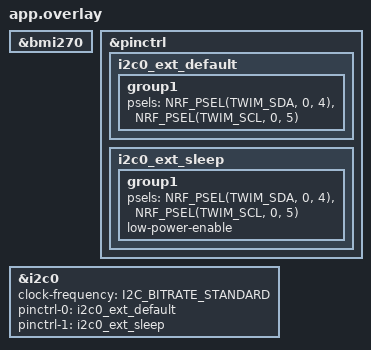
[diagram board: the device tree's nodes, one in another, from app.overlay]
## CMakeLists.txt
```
# Thingy:53 gait sensor node — integration firmware.
# Each sensor/radio module is compiled only when its Kconfig switch is on (see Kconfig).
# Every .c file is listed explicitly: a missing one gives "undefined reference".

cmake_minimum_required(VERSION 3.20.0)
find_package(Zephyr REQUIRED HINTS $ENV{ZEPHYR_BASE})
project(gait_node)

# Lets sources include "system/system_config.h", "imu/imu.h", ... from any subfolder
target_include_directories(app PRIVATE src src/plantar)

target_sources(app PRIVATE
    src/main.c
    src/data/data_queue.c
)

target_sources_ifdef(CONFIG_GAIT_IMU app PRIVATE
    src/imu/imu.c
    src/imu/imu_thread.c
)

target_sources_ifdef(CONFIG_GAIT_PLANTAR app PRIVATE
    src/plantar/fsr402.c
    src/plantar/plantar_thread.c
)

target_sources_ifdef(CONFIG_GAIT_BLE app PRIVATE
    src/ble/gait_ble.c
)

# BLE consumer requires both BLE and Plantar modules
if(CONFIG_GAIT_BLE AND CONFIG_GAIT_PLANTAR)
    target_sources(app PRIVATE src/ble/ble_thread.c)
endif()

# Fake data source for BLE testing without sensors (see Kconfig GAIT_MOCK_DATA)
target_sources_ifdef(CONFIG_GAIT_MOCK_DATA app PRIVATE
    src/mock/mock_signal.c
    src/mock/mock_thread.c
)
```

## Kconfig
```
# Module switches for the gait node. Turn a module off in prj.conf if it is not ready;
# the rest of the firmware still builds and runs.

menu "Gait node modules"

config GAIT_IMU
	bool "BMI270 IMU module (src/imu)"
	default y
	select SENSOR

config GAIT_PLANTAR
	bool "FSR 402 plantar pressure module via Adafruit ADS7128 (I2C)"
	default n
	depends on I2C
	help
	  Enable the six-channel FSR402 interface using the Adafruit ADS7128
	  8-channel, 12-bit ADC over the dedicated external I2C bus.

config GAIT_BLE
	bool "BLE streaming to the i.MX95 (src/ble)"
	default n
	help
	  Off until protocol/BLE_GAIT_PROTOCOL.md is agreed. When off, samples
	  are printed to the USB serial console instead.

config GAIT_MOCK_DATA
	bool "Send fake IMU/FSR data over BLE (no sensors needed)"
	default n
	depends on GAIT_BLE && GAIT_PLANTAR
	help
	  Skips imu_init()/fsr402_init() and the real sensor threads. A mock thread
	  generates a walking-like signal (stride 1.1 s) at 100 Hz instead. Use it to
	  test BLE and the receiver. Turn it off for real measurements.

endmenu

source "Kconfig.zephyr"
```

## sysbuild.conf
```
# The nRF5340 has two cores: this app runs on the
# application core, the BLE radio lives on the network core and needs its own image.

# Thingy:53 still relies on the Partition Manager; without it the network-core
# build fails with "undefined node label 's0_partition'".
SB_CONFIG_PARTITION_MANAGER=y

# Network core image: BLE controller (ipc_radio, HCI over IPC) instead of an empty image
SB_CONFIG_NETCORE_IPC_RADIO=y
SB_CONFIG_NETCORE_IPC_RADIO_BT_HCI_IPC=y

# One merged hex for app + network core
SB_CONFIG_MERGED_HEX_FILES=y

SB_CONFIG_BOOTLOADER_MCUBOOT=y
```

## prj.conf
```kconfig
# Console over USB (the board default USB stack provides the CDC ACM console)
CONFIG_STDOUT_CONSOLE=y
CONFIG_CBPRINTF_FP_SUPPORT=y
CONFIG_UART_LINE_CTRL=y

# MCUboot: app-side image manager, lets the app confirm a new image after boot.
# Optional, but needed if the app calls boot_write_img_confirmed().
CONFIG_MCUBOOT_IMG_MANAGER=y

# Modules
CONFIG_GAIT_IMU=y
CONFIG_GAIT_PLANTAR=y
CONFIG_GAIT_BLE=y

# ADS7128 communicates over I2C (not the nRF5340 internal SAADC).
CONFIG_I2C=y

# Needed by the BMI270 sensor driver
CONFIG_SENSOR=y

# Needed by the BLE module. Comment out together with CONFIG_GAIT_BLE=n.
CONFIG_BT=y
CONFIG_BT_PERIPHERAL=y
CONFIG_BT_DEVICE_NAME="GaitNode"
# Ask the central for a 7.5-15 ms connection interval (units of 1.25 ms)
CONFIG_BT_PERIPHERAL_PREF_MIN_INT=6
CONFIG_BT_PERIPHERAL_PREF_MAX_INT=12
CONFIG_BT_PERIPHERAL_PREF_LATENCY=0
CONFIG_BT_PERIPHERAL_PREF_TIMEOUT=400
# main() now runs printf with floats plus the BLE calls
CONFIG_MAIN_STACK_SIZE=4096
# More TX buffers so ~200 notifications/s (IMU + FSR at 100 Hz) are not dropped
CONFIG_BT_L2CAP_TX_MTU=247
CONFIG_BT_BUF_ACL_RX_SIZE=251
CONFIG_BT_BUF_ACL_TX_SIZE=251
CONFIG_BT_BUF_ACL_TX_COUNT=7
CONFIG_BT_L2CAP_TX_BUF_COUNT=7
CONFIG_BT_BUF_EVT_RX_COUNT=10

# Test BLE without sensors (fake walking data). Set to n for real measurements.
CONFIG_GAIT_MOCK_DATA=y
```

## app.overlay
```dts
/*
 * Thingy:53 gait_node overlay
 *
 * BMI270 remains enabled on the board's existing SPI bus.
 *
 * ADS7128 uses a dedicated external I2C bus
 * on the Thingy:53 expansion pins:
 *   P0.04 = EXP_BOARD_PIN1 = SDA
 *   P0.05 = EXP_BOARD_PIN2 = SCL
 *
 * ADS7128 factory I2C address: 0x10
 *
 * This overlay uses i2c0 on P0.04/P0.05,
 * not the Thingy:53 onboard-sensor i2c1 bus.
 */

#include <zephyr/dt-bindings/pinctrl/nrf-pinctrl.h>


/* IMU owner: BMI270 on SPI, unchanged. */
&bmi270 {
    status = "okay";
};


/* Dedicated external I2C bus for ADS7128. */
&pinctrl {

    i2c0_ext_default: i2c0_ext_default {
        group1 {
            psels = <NRF_PSEL(TWIM_SDA, 0, 4)>,
                    <NRF_PSEL(TWIM_SCL, 0, 5)>;
        };
    };

    i2c0_ext_sleep: i2c0_ext_sleep {
        group1 {
            psels = <NRF_PSEL(TWIM_SDA, 0, 4)>,
                    <NRF_PSEL(TWIM_SCL, 0, 5)>;
            low-power-enable;
        };
    };
};


/* External ADS7128 I2C controller. */
&i2c0 {
    status = "okay";
    clock-frequency = <I2C_BITRATE_STANDARD>;

    pinctrl-0 = <&i2c0_ext_default>;
    pinctrl-1 = <&i2c0_ext_sleep>;
    pinctrl-names = "default", "sleep";
};
```

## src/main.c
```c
/*
 * gait_node main:
 * Initialise modules and start sensor threads.
 * Each sensor is read only by its own sampling thread.
 */

#include <stdio.h>
#include <stdint.h>
#include <stdbool.h>

#include <zephyr/kernel.h>
#include <zephyr/device.h>
#include <zephyr/drivers/uart.h>

#ifdef CONFIG_GAIT_IMU
#include "imu/imu.h"
#include "imu/imu_thread.h"
#endif

#ifdef CONFIG_GAIT_PLANTAR
#include "plantar/fsr402.h"
#include "plantar/plantar_thread.h"
#endif

#ifdef CONFIG_GAIT_BLE
#include "ble/gait_ble.h"
#endif
#if defined(CONFIG_GAIT_BLE) && defined(CONFIG_GAIT_PLANTAR)
#include "ble/ble_thread.h"
#endif
#ifdef CONFIG_GAIT_MOCK_DATA
#include "mock/mock_thread.h"
#endif

int main(void)
{
    uint32_t dtr = 0;
    const struct device *uart =
        DEVICE_DT_GET(DT_CHOSEN(zephyr_console));

    /* Wait for USB serial host (up to 30 seconds) */
    for (int i = 0; i < 300 && !dtr; i++) {
        uart_line_ctrl_get(
            uart,
            UART_LINE_CTRL_DTR,
            &dtr
        );
        k_msleep(100);
    }

    k_msleep(500);

    printf("\n=== GAIT NODE STARTING ===\n");

#ifdef CONFIG_GAIT_MOCK_DATA
    printf("MOCK DATA MODE: sensors are NOT read, BLE sends fake data\n");
    bool imu_ready = false;
    bool fsr_ready = true; /* lets ble_thread start */
#else
#ifdef CONFIG_GAIT_IMU
    bool imu_ready = (imu_init() == 0);

    printf(imu_ready ?
           "BMI270 initialized\n" :
           "BMI270 initialization failed\n");
#endif

#ifdef CONFIG_GAIT_PLANTAR
    bool fsr_ready = (fsr402_init() == 0);

    printf(fsr_ready ?
           "FSR402 ADS7128 initialized\n" :
           "FSR402 ADS7128 initialization failed\n");
#endif
#endif /* CONFIG_GAIT_MOCK_DATA */

#ifdef CONFIG_GAIT_BLE
    /* Initialize Bluetooth */
    int ble_rc = gait_ble_init();

    bool ble_ready = (ble_rc == 0);

    if (!ble_ready) {
        printf("BLE init failed: rc=%d\n", ble_rc);
    }
#endif

#ifdef CONFIG_GAIT_MOCK_DATA
    if (mock_thread_start() == 0) {
        printf("Mock data thread started\n");
    }
#endif

#ifdef CONFIG_GAIT_IMU
    if (imu_ready) {
        int rc = imu_thread_start();

        if (rc != 0) {
            printf("IMU thread start failed: %d\n", rc);
        } else {
            printf("IMU sampling thread started\n");
        }
    }
#endif

#if defined(CONFIG_GAIT_PLANTAR) && !defined(CONFIG_GAIT_MOCK_DATA)
    if (fsr_ready) {
        int rc = plantar_thread_start();

        if (rc != 0) {
            printf("FSR thread start failed: %d\n", rc);
        } else {
            printf("FSR sampling thread started\n");
        }
    }
#endif
#if defined(CONFIG_GAIT_BLE) && defined(CONFIG_GAIT_PLANTAR)
    if (ble_ready && fsr_ready) {
        int rc = ble_thread_start();

        if (rc != 0) {
            printf("BLE consumer thread start failed: %d\n", rc);
        } else {
            printf("BLE consumer thread started\n");
        }
    }
#endif

    printf("\n=== GAIT NODE SAMPLING STARTED ===\n");

    return 0;
}
```
